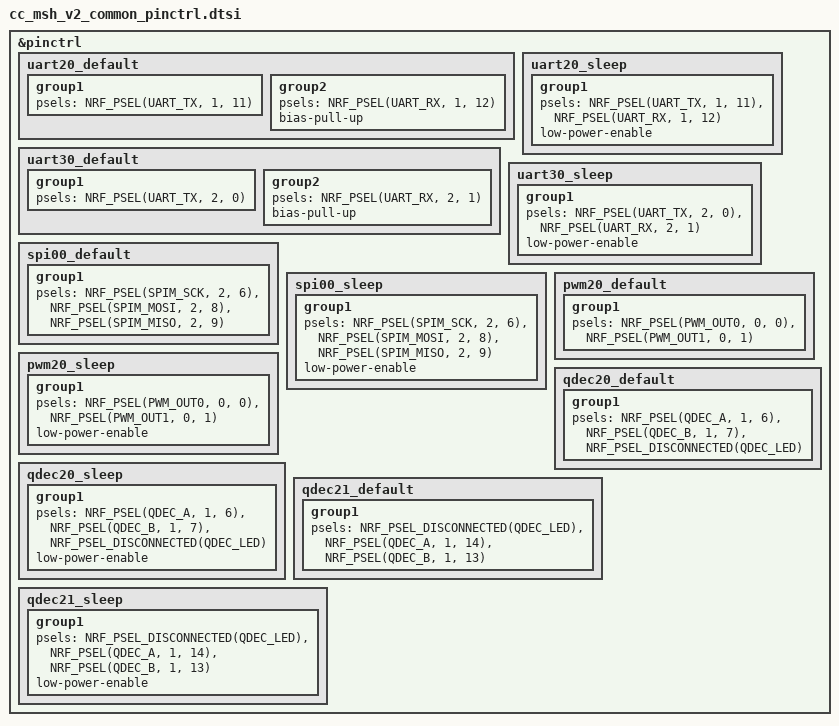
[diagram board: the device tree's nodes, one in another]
/*
 * Copyright (c) 2025 Classified Cycling BV
 *
 * SPDX-License-Identifier: Apache-2.0
 */

&pinctrl {
	/omit-if-no-ref/ uart20_default: uart20_default {
		group1 {
			psels = <NRF_PSEL(UART_TX, 1, 11)>;
		};
		group2 {
			psels = <NRF_PSEL(UART_RX, 1, 12)>;
			bias-pull-up;
		};
	};

	/omit-if-no-ref/ uart20_sleep: uart20_sleep {
		group1 {
			psels = <NRF_PSEL(UART_TX, 1, 11)>,
			        <NRF_PSEL(UART_RX, 1, 12)>;
			low-power-enable;
		};
	};

	/omit-if-no-ref/ uart30_default: uart30_default {
		group1 {
			psels = <NRF_PSEL(UART_TX, 2, 0)>;
		};
		group2 {
			psels = <NRF_PSEL(UART_RX, 2, 1)>;
			bias-pull-up;
		};
	};

	/omit-if-no-ref/ uart30_sleep: uart30_sleep {
		group1 {
			psels = <NRF_PSEL(UART_TX, 2, 0)>,
			        <NRF_PSEL(UART_RX, 2, 1)>;
			low-power-enable;
		};
	};

	/omit-if-no-ref/ spi00_default: spi00_default {
		group1 {
			psels = <NRF_PSEL(SPIM_SCK, 2, 6)>,
			        <NRF_PSEL(SPIM_MOSI, 2, 8)>,
			        <NRF_PSEL(SPIM_MISO, 2, 9)>;
		};
	};

	/omit-if-no-ref/ spi00_sleep: spi00_sleep {
		group1 {
			psels = <NRF_PSEL(SPIM_SCK, 2, 6)>,
			        <NRF_PSEL(SPIM_MOSI, 2, 8)>,
			        <NRF_PSEL(SPIM_MISO, 2, 9)>;
			low-power-enable;
		};
	};

	/omit-if-no-ref/ pwm20_default: pwm20_default {
		group1 {
			psels = <NRF_PSEL(PWM_OUT0, 0, 0)>,
			        <NRF_PSEL(PWM_OUT1, 0, 1)>;
		};
	};

	/omit-if-no-ref/ pwm20_sleep: pwm20_sleep {
		group1 {
			psels = <NRF_PSEL(PWM_OUT0, 0, 0)>,
			        <NRF_PSEL(PWM_OUT1, 0, 1)>;
			low-power-enable;
		};
	};

	/omit-if-no-ref/ qdec20_default: qdec20_default {
		group1 {
			/* Important: put QDEC_A always first, followed by QDEC_B */
			psels = <NRF_PSEL(QDEC_A, 1, 6)>,
			        <NRF_PSEL(QDEC_B, 1, 7)>,
			        <NRF_PSEL_DISCONNECTED(QDEC_LED)>;
		};
	};

	/omit-if-no-ref/ qdec20_sleep: qdec20_sleep {
		group1 {
			/* Important: put QDEC_A always first, followed by QDEC_B */
			psels = <NRF_PSEL(QDEC_A, 1, 6)>,
			        <NRF_PSEL(QDEC_B, 1, 7)>,
			        <NRF_PSEL_DISCONNECTED(QDEC_LED)>;
			low-power-enable;
		};
	};

	/omit-if-no-ref/ qdec21_default: qdec21_default {
		group1 {
			psels = <NRF_PSEL_DISCONNECTED(QDEC_LED)>,
			        <NRF_PSEL(QDEC_A, 1, 14)>,
			        <NRF_PSEL(QDEC_B, 1, 13)>;
		};
	};

	/omit-if-no-ref/ qdec21_sleep: qdec21_sleep {
		group1 {
			psels = <NRF_PSEL_DISCONNECTED(QDEC_LED)>,
			        <NRF_PSEL(QDEC_A, 1, 14)>,
			        <NRF_PSEL(QDEC_B, 1, 13)>;
			low-power-enable;
		};
	};
};
